AUTOSAR XML (schema 4-2-2)
package /AUTOLIV/SoftwareComponents/NVP
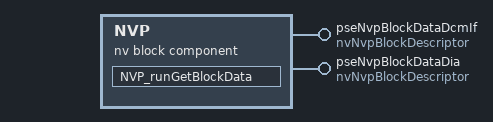
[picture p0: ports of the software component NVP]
  nv block sw component type NVP: category=SWC  # NVP_AC_NonVolatileParameters
    provide port pseNvpBlockDataDcmIf: provided-interface=nvNvpBlockDescriptor
      provided-com-specs:
        ram-block-init-value=KU8_NVP_PROCESS_MODE_INACTIVE, rom-block-init-value=KU8_NVP_PROCESS_MODE_INACTIVE, variable=u8NvpProcessMode
        u8NvpEcuLockStatus
    provide port pseNvpBlockDataDia: provided-com-specs=[u8NvpProcessMode, u8NvpEcuLockStatus], provided-interface=nvNvpBlockDescriptor
    behavior NVP_IB_NonVolatileParameters: data-type-mapping=DataTypeMappingSet_NVP, handle-termination-and-restart=NO-SUPPORT
      runnable NVP_runGetBlockData: can-be-invoked-concurrently=true
  swc implementation NVP_impNonVolatileParameters: category=SWC, programming-language=C, sw-version=1.0.0, vendor-id=0, behavior=NVP_IB_NonVolatileParameters
    code-descriptors:
      code NVP_Impl_Code_CodeDesc: artifact-descriptors=autosar-engineering-object={short-label=NVP_Impl_Code_CodeDesc, category=SWSRC}
    resource consumption NVP_Impl_ResCons
      5 x memory section, all with size=0:
        NVP_CONST_8: alignment=8, sw-addrmethod=CONST
        NVP_CONST_CAL_VERS_U32: alignment=32, sw-addrmethod=CONST  # NVP_CONST_CALIBRATION_VERSION_U32
        NVP_CONST_NVM_VERS_U32: alignment=32, sw-addrmethod=CONST  # NVP_CONST_NVM_VERSION_U32
        NVP_CONST_UNSPECIFIED: alignment=UNSPECIFIED, sw-addrmethod=CONST
        NVP_VAR_8: alignment=8, sw-addrmethod=VAR
